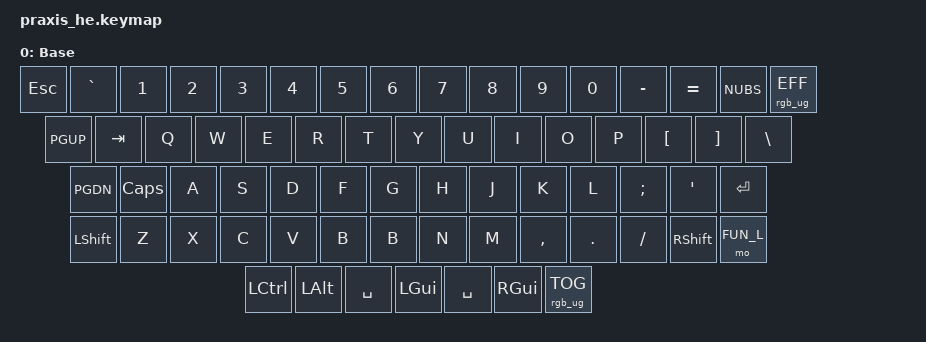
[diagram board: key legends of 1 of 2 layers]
/*
 * Copyright (c) 2020 The ZMK Contributors
 *
 * SPDX-License-Identifier: MIT
 */

#include <behaviors.dtsi>
#include <dt-bindings/zmk/bt.h>
#include <dt-bindings/zmk/keys.h>
#include <dt-bindings/zmk/rgb.h>

#define BASE_L	0
#define FUN_L	1

/ {
    keymap {
        compatible = "zmk,keymap";

        base_layer {
            display-name = "Base";
            bindings = <
       &kp ESC &kp GRAVE &kp N1      &kp N2      &kp N3       &kp N4          &kp N5         &kp N6            &kp N7          &kp N8       &kp N9      &kp N0   &kp MINUS &kp EQUAL &kp NUBS &rgb_ug RGB_EFF
      &kp PGUP &kp TAB &kp Q      &kp W      &kp E       &kp R          &kp T         &kp Y            &kp U          &kp I       &kp O      &kp P   &kp LBKT &kp RBKT &kp BSLH
     &kp PGDN &kp CAPS &kp A      &kp S      &kp D       &kp F          &kp G         &kp H            &kp J          &kp K       &kp L  &kp SEMI    &kp QUOT &kp RET
       &kp LSHIFT &kp Z      &kp X      &kp C       &kp V          &kp B         &kp B &kp N            &kp M          &kp COMMA   &kp DOT    &kp FSLH &kp RSHFT &mo FUN_L
             &kp LCTL &kp LALT &kp SPC &kp LGUI                        &kp SPC &kp RGUI &rgb_ug RGB_TOG
            >;
        };

        fun_layer {
            display-name = "Fn";
            bindings = <
	&trans &trans &trans &trans &trans &trans &trans         &trans  &trans         &trans       &trans      &trans   &trans &trans &trans  &studio_unlock
      &trans &trans &trans      &trans      &trans       &trans          &trans         &trans            &trans          &trans       &trans      &trans   &trans &trans &trans
     &bootloader &trans &trans      &trans      &trans       &trans          &trans         &trans            &trans          &trans       &trans  &trans    &trans &trans
       &trans &trans      &trans      &trans       &trans          &trans         &trans            &trans          &trans   &trans    &trans &trans &trans
             &trans &trans &trans &trans                        &trans &trans &rgb_ug RGB_TOG
            >;
        };

	res1 { status = "reserved"; };
	res2 { status = "reserved"; };
	res3 { status = "reserved"; };
	res4 { status = "reserved"; };
    };
};
